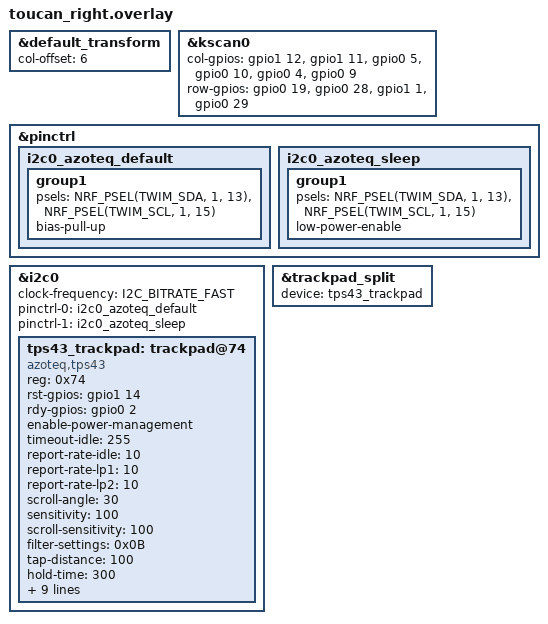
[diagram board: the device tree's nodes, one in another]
#include "toucan.dtsi"

&default_transform {
    col-offset = <6>;
};

&kscan0 {
    col-gpios
    = <&gpio1 12 GPIO_ACTIVE_HIGH>
    , <&gpio1 11 GPIO_ACTIVE_HIGH>
    , <&gpio0 5 GPIO_ACTIVE_HIGH>
    , <&gpio0 10 GPIO_ACTIVE_HIGH>
    , <&gpio0 4 GPIO_ACTIVE_HIGH>
    , <&gpio0 9 GPIO_ACTIVE_HIGH>
    ;

    row-gpios
    = <&gpio0 19 (GPIO_ACTIVE_HIGH | GPIO_PULL_DOWN)>
    , <&gpio0 28 (GPIO_ACTIVE_HIGH | GPIO_PULL_DOWN)>
    , <&gpio1 1 (GPIO_ACTIVE_HIGH | GPIO_PULL_DOWN)>
    , <&gpio0 29 (GPIO_ACTIVE_HIGH | GPIO_PULL_DOWN)>
    ;
};

&pinctrl {
    i2c0_azoteq_default: i2c0_azoteq_default {
        group1 {
            psels = <NRF_PSEL(TWIM_SDA, 1, 13)>,
                    <NRF_PSEL(TWIM_SCL, 1, 15)>;
            bias-pull-up;
        };
    };

    i2c0_azoteq_sleep: i2c0_azoteq_sleep {
        group1 {
            psels = <NRF_PSEL(TWIM_SDA, 1, 13)>,
                    <NRF_PSEL(TWIM_SCL, 1, 15)>;
            low-power-enable;
        };
    };
};

&i2c0 {
   status = "okay";
    clock-frequency = <I2C_BITRATE_FAST>;
    pinctrl-0 = <&i2c0_azoteq_default>;
    pinctrl-1 = <&i2c0_azoteq_sleep>;
    pinctrl-names = "default", "sleep";

    tps43_trackpad: trackpad@74 {
        compatible = "azoteq,tps43";
        reg = <0x74>;
        status = "okay";

        rst-gpios = <&gpio1 14 GPIO_ACTIVE_HIGH>;
        rdy-gpios = <&gpio0 2 GPIO_ACTIVE_HIGH>;

        enable-power-management;
        // idle-sleep; // provides maximal power savings but when ZMK is idle (i.e. you haven't used keyboard in 30secs) the touchpad will not work.  not recommended.
        // timeout-lp1 = <3>; // 60s timeout before entering lp2 state (20 secs per unit) (default was 20s)
        // Keep the pad responsive for as long as ZMK is awake: the chip's own
        // idle -> LP1 -> LP2 ladder slowed scanning to 640ms, which is the lag
        // on first touch. 255 = never leave idle mode, and the LP rates match
        // active anyway in case it does. Costs ~2-3mA vs ~55uA in LP2; the pad
        // still suspends when ZMK deep-sleeps (CONFIG_ZMK_IDLE_SLEEP_TIMEOUT).
        timeout-idle = <255>;
        report-rate-idle = <10>;
        report-rate-lp1 = <10>;
        report-rate-lp2 = <10>;
        scroll-angle = <30>; // The default angle (about 47 deg) is too big on toucan2 I think
        sensitivity = <100>;
        scroll-sensitivity = <100>;

        filter-settings=<0x0B>;
        // press-and-hold only fires if the finger stays inside tap-distance for
        // the whole hold-time, so 500ms with the hardware default distance was
        // easy to miss. Shorter hold, more slack on the drift.
        tap-distance = <100>;
        hold-time = <300>;

        zoom;
        scroll;
        two-finger-tap;
        single-tap;
        press-and-hold;
        //swipes;
        three-finger-swipe;
        three-finger-swipe-throttle-ms = <1200>;
        switch-xy;
        invert-scroll-y;

    };
};

&trackpad_split {
    device = <&tps43_trackpad>;
};
